# STM32U073 register map
File version: 1.0
CPU: CM0+ r0p1, little endian, MPU, no FPU, 4 interrupt priority bits
Registers are 32-bit, read-write, reset 0x0 unless marked. A register's access mark holds for its fields unless they carry their own. Offsets are from the block's base; [hi:lo] are bit positions; {n}, {i} and the like mark numbered series.

## PWR — PWR register block
Base 0x40007000
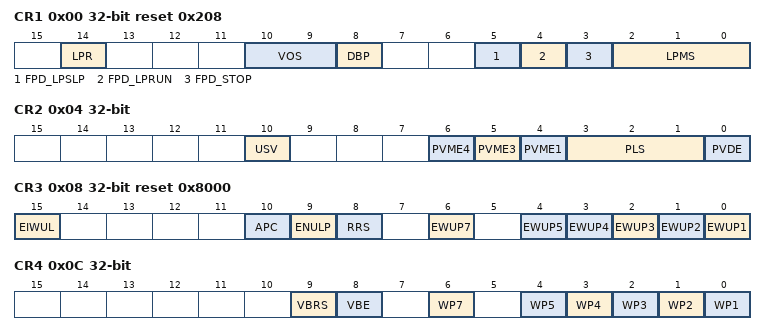
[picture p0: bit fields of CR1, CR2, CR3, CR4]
0x00 CR1 reset 0x208 — Power control register 1
  [14] LPR — Low-power run When this bit is set, the regulator is switched from main mode (MR) to low-power mode (LPR). Note: Stop 2 mode cannot be entered when LPR bit is set. Stop 1 is entered instead.
  [10:9] VOS — Voltage scaling range selection
  [8] DBP — Disable backup domain write protection In reset state, the RTC and backup registers are protected against parasitic write access. This bit must be set to enable write access to these registers.
  [5] FPD_LPSLP — Flash memory powered down during Low-power sleep mode. This bit determines whether the flash memory is put in power-down mode or remains in idle mode when the device enters Low-power sleep mode.
  [4] FPD_LPRUN — Flash memory powered down during Low-power run mode. This bit determines whether the flash memory is put in power-down mode or remains in idle mode when the device enters Low-power sleep mode.
  [3] FPD_STOP — Flash memory powered down during Stop mode. This bit determines whether the flash memory is put in power-down mode or remains in idle mode when the device enters Stop mode.
  [2:0] LPMS — Low-power mode selection These bits select the low-power mode entered when CPU enters the deepsleep mode. 1xx: Shutdown mode Note: If LPR bit is set, Stop 2 mode cannot be selected and Stop 1 mode shall be entered instead of Stop 2. Note: In Standby mode, SRAM2 can be preserved or not, depending on RRS bit configuration in PWR_CR3.
0x04 CR2 — Power control register 2
  [10] USV — V<sub>DDUSB</sub> USB supply valid This bit is used to validate the V<sub>DDUSB</sub> supply for electrical and logical isolation purpose. Setting this bit is mandatory to use the USB FS peripheral. If V<sub>DDUSB</sub> is not always present in the application, the PVM can be used to determine whether this supply is ready or not.
  [6] PVME4 — Peripheral voltage monitoring 4 enable: V<sub>DDA</sub> vs. 1.861V
  [5] PVME3 — Peripheral voltage monitoring 3 enable: V<sub>DDA</sub> vs. 1.621V
  [4] PVME1 — Peripheral voltage monitoring 1 enable: V<sub>DDUSB</sub> vs. 1.21V
  [3:1] PLS — Programmable voltage detector level selection. These bits select the voltage threshold detected by the programmable voltage detector: Note: These bits are write-protected when the bit PVDL (PVD Lock) is set in the SYSCFG_CBR register. Note: These bits are reset only by a system reset.
  [0] PVDE — Programmable voltage detector enable Note: This bit is write-protected when the bit PVDL (PVD Lock) is set in the SYSCFG_CBR register. Note: This bit is reset only by a system reset.
0x08 CR3 reset 0x8000 — Power control register 3
  [15] EIWUL — Enable internal wake-up line
  [10] APC — Apply pull-up and pull-down configuration When this bit is set, the I/O pull-up and pull-down configurations defined in the PWR_PUCRx and PWR_PDCRx registers are applied. When this bit is cleared, the PWR_PUCRx and PWR_PDCRx registers are not applied to the I/Os, instead the I/Os are in floating mode during Standby or configured according GPIO controller GPIOx_PUPDR register during RUN mode.
  [9] ENULP — Enable ULP sampling When this bit is set, the BORL, BORH and PVD are periodically sampled instead continuous monitoring to reduce power consumption. Fast supply drop between two sample/compare phases is not detected in this mode. This bit has impact only on STOP2, Standby and shutdown low power modes.
  [8] RRS — SRAM2 retention in Standby mode
  [6] EWUP7 — Enable Wake-up pin WKUP7. When this bit is set, the external wake-up pin WKUP7 is enabled and triggers a wake-up from Standby or Shutdown event when a rising or a falling edge occurs.The active edge is configured via the WP7 bit in the PWR_CR4 register.
  [4] EWUP5 — Enable Wake-up pin WKUP5 When this bit is set, the external wake-up pin WKUP5 is enabled and triggers a wake-up from Standby or Shutdown event when a rising or a falling edge occurs.The active edge is configured via the WP5 bit in the PWR_CR4 register.
  [n-1] EWUP{n} (n=1..4) — Enable Wake-up pin WKUP{n} When this bit is set, the external wake-up pin WKUP{n} is enabled and triggers a wake-up from Standby or Shutdown event when a rising or a falling edge occurs. The active edge is configured via the WP{n} bit in the PWR_CR4 register.
0x0C CR4 — Power control register 4
  [9] VBRS — V<sub>BAT</sub> battery charging resistor selection
  [8] VBE — V<sub>BAT</sub> battery charging enable
  [6] WP7 — Wake-up pin WKUP7 polarity This bit defines the polarity used for an event detection on external wake-up pin, WKUP7
  [n-1] WP{n} (n=1..5) — Wake-up pin WKUP{n} polarity This bit defines the polarity used for an event detection on external wake-up pin, WKUP{n}
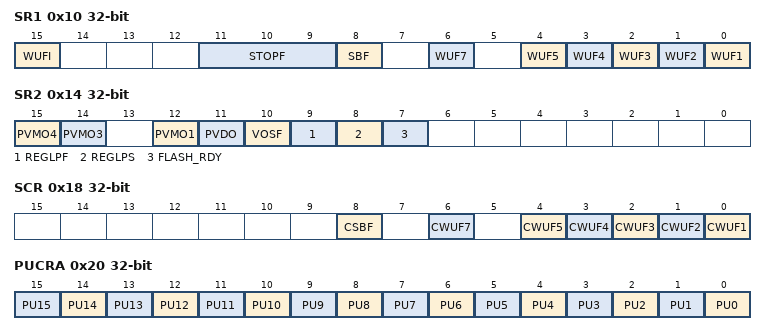
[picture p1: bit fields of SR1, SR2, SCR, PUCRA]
0x10 SR1 ro — Power status register 1
  [15] WUFI — Wake-up flag internal This bit is set when a wake-up is detected on the internal wake-up line. It is cleared when all internal wake-up sources are cleared.
  [11:9] STOPF — Stop Flags These bits are set by hardware when the device enters any stop mode and are cleared by setting the CSBF bit in the PWR_SCR register, or by a power-on reset. It is not cleared by the system reset.
  [8] SBF — Standby flag This bit is set by hardware when the device enters the Standby mode and is cleared by setting the CSBF bit in the PWR_SCR register, or by a power-on reset. It is not cleared by the system reset.
  [6] WUF7 — Wake-up flag 7 This bit is set when a wake-up event is detected on wake-up pin, WKUP7. It is cleared by writing 1 in the CWUF7 bit of the PWR_SCR register.
  [4] WUF5 — Wake-up flag 5 This bit is set when a wake-up event is detected on wake-up pin, WKUP5. It is cleared by writing 1 in the CWUF5 bit of the PWR_SCR register.
  [3] WUF4 — Wake-up flag 4 This bit is set when a wake-up event is detected on wake-up pin,WKUP4. It is cleared by writing 1 in the CWUF4 bit of the PWR_SCR register.
  [2] WUF3 — Wake-up flag 3 This bit is set when a wake-up event is detected on wake-up pin, WKUP3. It is cleared by writing 1 in the CWUF3 bit of the PWR_SCR register.
  [1] WUF2 — Wake-up flag 2 This bit is set when a wake-up event is detected on wake-up pin, WKUP2. It is cleared by writing 1 in the CWUF2 bit of the PWR_SCR register.
  [0] WUF1 — Wake-up flag 1 This bit is set when a wake-up event is detected on wake-up pin, WKUP1. It is cleared by writing 1 in the CWUF1 bit of the PWR_SCR register.
0x14 SR2 ro — Power status register 2
  [15] PVMO4 — Peripheral voltage monitoring output: V<sub>DDA</sub> vs. 2.21V Note: PVMO4 is cleared when PVM4 is disabled (PVME4 = 0). After enabling PVM4, the PVM4 output is valid after the PVM4 wake-up time.
  [14] PVMO3 — Peripheral voltage monitoring output: V<sub>DDA</sub> vs. 1.621V Note: PVMO3 is cleared when PVM3 is disabled (PVME3 = 0). After enabling PVM3, the PVM3 output is valid after the PVM3 wake-up time.
  [12] PVMO1 — Peripheral voltage monitoring output: V<sub>DDUSB</sub> vs. 1.2 V Note: PVMO1 is cleared when PVM1 is disabled (PVME1 = 0). After enabling PVM1, the PVM1 output is valid after the PVM1 wake-up time.
  [11] PVDO — Programmable voltage detector output
  [10] VOSF — Voltage scaling flag A delay is required for the internal regulator to be ready after the voltage scaling has been changed. VOSF indicates that the regulator reached the voltage level defined with VOS bits of the PWR_CR1 register.
  [9] REGLPF — Low-power regulator flag This bit is set by hardware when the MCU is in Low-power run mode. When the MCU exits from the Low-power run mode, this bit remains at 1 until the regulator is ready in main mode. A polling on this bit must be done before increasing the product frequency. This bit is cleared by hardware when the regulator is ready.
  [8] REGLPS — Low-power regulator started This bit provides the information whether the low-power regulator is ready after a power-on reset or a Standby/Shutdown. If the Standby mode is entered while REGLPS bit is still cleared, the wake-up from Standby mode time may be increased.
  [7] FLASH_RDY — Flash ready flag This bit is set by hardware to indicate when the flash memory is readey to be accessed after wake-up from power-down. To place the flash memory in power-down, set either FPD_LPRUN, FPD_LPSLP or FPD_STP bits. Note : If the system boots from SRAM, the user application must wait until the FLASH_RDY bit is set, prior to jumping to flash memory.
0x18 SCR wo — Power status clear register
  [8] CSBF — Clear standby flag Setting this bit clears the SBF flag in the PWR_SR1 register.
  [6] CWUF7 — Clear wake-up flag 7 Setting this bit clears the WUF7 flag in the PWR_SR1 register.
  [n-1] CWUF{n} (n=1..5) — Clear wake-up flag {n} Setting this bit clears the WUF{n} flag in the PWR_SR1 register.
0x20 PUCRA — Power Port A pull-up control register
  [n] PU{n} (n=0..15) — Port A pull-up bit y (y1=115 to 0) When set, this bit activates the pull-up on PA[y] when APC bit is set in PWR_CR3 register. If the corresponding PDy bit is also set, the pull-up is not activated and the pull-down is activated instead with highest priority.
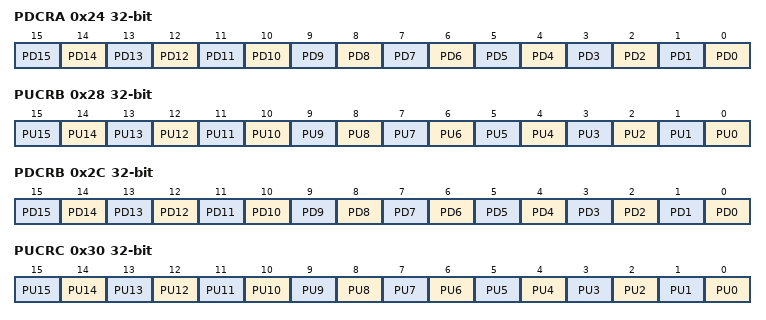
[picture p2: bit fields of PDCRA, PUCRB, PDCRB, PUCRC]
0x24 PDCRA — Power Port A pull-down control register
  [n] PD{n} (n=0..15) — Port A pull-down bit y When set, this bit activates the pull-down on PA[y] when APC bit is set in PWR_CR3 register.
0x28 PUCRB — Power Port B pull-up control register
  [n] PU{n} (n=0..15) — Port B pull-up bit y When set, this bit activates the pull-up on PB[y] when APC bit is set in PWR_CR3 register.
0x2C PDCRB — Power Port B pull-down control register
  [n] PD{n} (n=0..15) — Port B pull-down bit y When set, this bit activates the pull-down on PB[y] when APC bit is set in PWR_CR3 register.
0x30 PUCRC — Power Port C pull-up control register
  [n] PU{n} (n=0..15) — Port C pull-up bit y When set, this bit activates the pull-up on PC[y] when APC bit is set in PWR_CR3 register. If the corresponding PDy bit is also set, the pull-up is not activated and the pull-down is activated instead with highest priority.
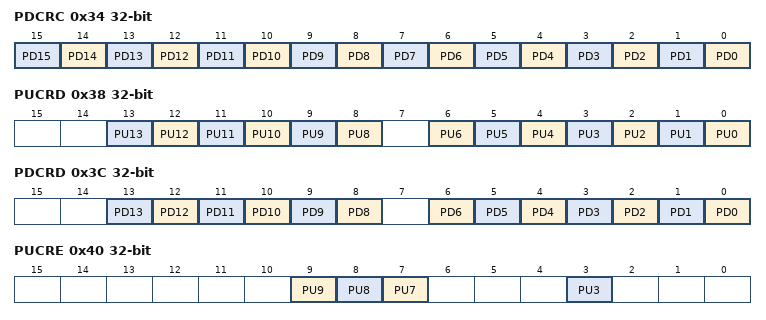
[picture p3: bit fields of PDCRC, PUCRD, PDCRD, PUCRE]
0x34 PDCRC — Power Port C pull-down control register
  [n] PD{n} (n=0..15) — Port C pull-down bit y When set, this bit activates the pull-down on PC[y] when APC bit is set in PWR_CR3 register.
0x38 PUCRD — Power Port D pull-up control register
  [n] PU{n} (n=8..13) — Port D pull-up bit y When set, this bit activates the pull-up on PD[y] when APC bit is set in PWR_CR3 register. If the corresponding PDy bit is also set, the pull-up is not activated and the pull-down is activated instead with highest priority.
  [n] PU{n} (n=0..6) — Port D pull-up bit y When set, this bit activates the pull-up on PD[y] when APC bit is set in PWR_CR3 register. If the corresponding PDy bit is also set, the pull-up is not activated and the pull-down is activated instead with highest priority.
0x3C PDCRD — Power Port D pull-down control register
  [n] PD{n} (n=8..13) — Port D pull-down bit y When set, this bit activates the pull-down on PD[y] when APC bit is set in PWR_CR3 register.
  [n] PD{n} (n=0..6) — Port D pull-down bit y When set, this bit activates the pull-down on PD[y] when APC bit is set in PWR_CR3 register.
0x40 PUCRE — Power Port E pull-up control register
  [9] PU9 — Port E pull-up bit y When set, this bit activates the pull-up on PE[y] when APC bit is set in PWR_CR3 register. If the corresponding PDy bit is also set, the pull-up is not activated and the pull-down is activated instead with highest priority.
  [8] PU8 — Port E pull-up bit y When set, this bit activates the pull-up on PE[y] when APC bit is set in PWR_CR3 register. If the corresponding PDy bit is also set, the pull-up is not activated and the pull-down is activated instead with highest priority.
  [7] PU7 — Port E pull-up bit y When set, this bit activates the pull-up on PE[y] when APC bit is set in PWR_CR3 register. If the corresponding PDy bit is also set, the pull-up is not activated and the pull-down is activated instead with highest priority.
  [3] PU3 — Port E pull-up bit 3 When set, this bit activates the pull-up on PE[y] when APC bit is set in PWR_CR3 register. If the corresponding PDy bit is also set, the pull-up is not activated and the pull-down is activated instead with highest priority.
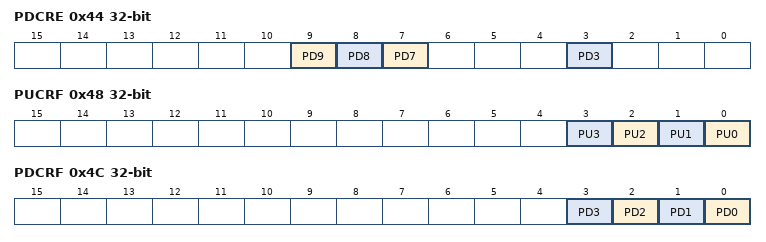
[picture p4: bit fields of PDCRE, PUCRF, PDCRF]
0x44 PDCRE — Power Port E pull-down control register
  [9] PD9 — Port E pull-down bit y When set, this bit activates the pull-down on PE[y] when APC bit is set in PWR_CR3 register.
  [8] PD8 — Port E pull-down bit y When set, this bit activates the pull-down on PE[y] when APC bit is set in PWR_CR3 register.
  [7] PD7 — Port E pull-down bit y When set, this bit activates the pull-down on PE[y] when APC bit is set in PWR_CR3 register.
  [3] PD3 — Port E pull-down bit 3 When set, this bit activates the pull-down on PE[y] when APC bit is set in PWR_CR3 register.
0x48 PUCRF — Power Port F pull-up control register
  [n] PU{n} (n=0..3) — Port F pull-up bit y When set, this bit activates the pull-up on PH[y] when APC bit is set in PWR_CR3 register. If the corresponding PDy bit is also set, the pull-up is not activated and the pull-down is activated instead with highest priority.
0x4C PDCRF — Power Port F pull-down control register
  [n] PD{n} (n=0..3) — Port F pull-down bit y When set, this bit activates the pull-down on PH[y] when APC bit is set in PWR_CR3 register.
